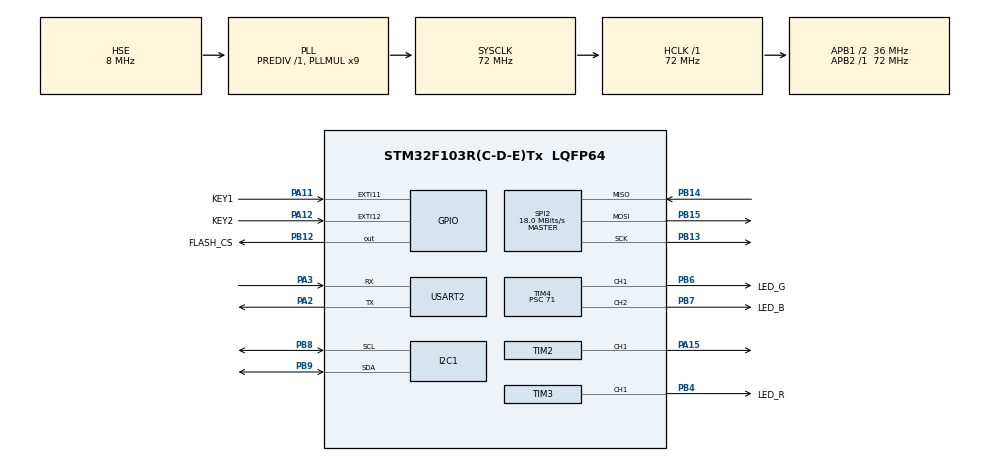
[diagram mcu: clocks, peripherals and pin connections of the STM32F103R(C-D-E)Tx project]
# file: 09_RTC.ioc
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Mcu.Family=STM32F1
Mcu.Name=STM32F103R(C-D-E)Tx
Mcu.Package=LQFP64
NVIC.PriorityGroup=NVIC_PRIORITYGROUP_4
NVIC.RTC_IRQn=true\:0\:0\:false\:false\:true\:true\:true\:true
NVIC.USART2_IRQn=true\:0\:0\:false\:false\:true\:true\:true\:true
PA11.GPIO_Label=KEY1
PA11.GPIO_ModeDefaultEXTI=GPIO_MODE_IT_RISING_FALLING
PA11.GPIO_PuPd=GPIO_PULLUP
PA11.Signal=GPXTI11
PA12.GPIO_Label=KEY2
PA12.GPIO_ModeDefaultEXTI=GPIO_MODE_IT_RISING_FALLING
PA12.GPIO_PuPd=GPIO_PULLUP
PA12.Signal=GPXTI12
PA13.Mode=Serial_Wire
PA13.Signal=SYS_JTMS-SWDIO
PA14.Mode=Serial_Wire
PA14.Signal=SYS_JTCK-SWCLK
PA15.GPIO_Speed=GPIO_SPEED_FREQ_HIGH
PA15.Signal=S_TIM2_CH1_ETR
PA2.Mode=Asynchronous
PA2.Signal=USART2_TX
PA3.Mode=Asynchronous
PA3.Signal=USART2_RX
PB12.GPIO_Label=FLASH_CS
PB12.GPIO_PuPd=GPIO_PULLUP
PB12.GPIO_Speed=GPIO_SPEED_FREQ_HIGH
PB12.PinState=GPIO_PIN_SET
PB12.Signal=GPIO_Output
PB13.Mode=Full_Duplex_Master
PB13.Signal=SPI2_SCK
PB14.Mode=Full_Duplex_Master
PB14.Signal=SPI2_MISO
PB15.Mode=Full_Duplex_Master
PB15.Signal=SPI2_MOSI
PB4.GPIO_Label=LED_R
PB4.GPIO_Speed=GPIO_SPEED_FREQ_HIGH
PB4.Signal=S_TIM3_CH1
PB6.GPIO_Label=LED_G
PB6.GPIO_Speed=GPIO_SPEED_FREQ_HIGH
PB6.Signal=S_TIM4_CH1
PB7.GPIO_Label=LED_B
PB7.GPIO_Speed=GPIO_SPEED_FREQ_HIGH
PB7.Signal=S_TIM4_CH2
PB8.Mode=I2C
PB8.Signal=I2C1_SCL
PB9.Mode=I2C
PB9.Signal=I2C1_SDA
PC14-OSC32_IN.Mode=LSE-External-Oscillator
PC14-OSC32_IN.Signal=RCC_OSC32_IN
PC15-OSC32_OUT.Mode=LSE-External-Oscillator
PC15-OSC32_OUT.Signal=RCC_OSC32_OUT
PD0-OSC_IN.Mode=HSE-External-Oscillator
PD0-OSC_IN.Signal=RCC_OSC_IN
PD1-OSC_OUT.Mode=HSE-External-Oscillator
PD1-OSC_OUT.Signal=RCC_OSC_OUT
ProjectManager.HeapSize=0x200
ProjectManager.StackSize=0x400
ProjectManager.TargetToolchain=MDK-ARM V5.32
RCC.AHBFreq_Value=72000000
RCC.APB1CLKDivider=RCC_HCLK_DIV2
RCC.APB1Freq_Value=36000000
RCC.APB1TimFreq_Value=72000000
RCC.APB2Freq_Value=72000000
RCC.APB2TimFreq_Value=72000000
RCC.HCLKFreq_Value=72000000
RCC.PLLMUL=RCC_PLL_MUL9
RCC.PLLSourceVirtual=RCC_PLLSOURCE_HSE
RCC.RTCClockSelection=RCC_RTCCLKSOURCE_LSE
RCC.SYSCLKFreq_VALUE=72000000
RCC.SYSCLKSource=RCC_SYSCLKSOURCE_PLLCLK
RCC.USBFreq_Value=72000000
RTC.AutoPrediv=RTC_AUTO_1_SECOND
RTC.Date=27
RTC.Format=RTC_FORMAT_BCD
RTC.Minutes=59
RTC.Month=RTC_MONTH_DECEMBER
RTC.OutPut=RTC_OUTPUTSOURCE_ALARM
RTC.Seconds=16
RTC.WeekDay=RTC_WEEKDAY_SATURDAY
RTC.Year=25
SH.S_TIM2_CH1_ETR.0=TIM2_CH1,PWM Generation1 CH1
SH.S_TIM3_CH1.0=TIM3_CH1,PWM Generation1 CH1
SH.S_TIM4_CH1.0=TIM4_CH1,PWM Generation1 CH1
SH.S_TIM4_CH2.0=TIM4_CH2,PWM Generation2 CH2
SPI2.CLKPhase=SPI_PHASE_2EDGE
SPI2.CLKPolarity=SPI_POLARITY_HIGH
SPI2.CalculateBaudRate=18.0 MBits/s
SPI2.Direction=SPI_DIRECTION_2LINES
SPI2.Mode=SPI_MODE_MASTER
SPI2.VirtualType=VM_MASTER
TIM1.AutoReloadPreload=TIM_AUTORELOAD_PRELOAD_ENABLE
TIM1.Period=9999
TIM1.Prescaler=71
TIM2.Channel-PWM\ Generation1\ CH1=TIM_CHANNEL_1
TIM2.OCPolarity_1=TIM_OCPOLARITY_LOW
TIM2.Period=99
TIM2.Prescaler=71
TIM3.AutoReloadPreload=TIM_AUTORELOAD_PRELOAD_ENABLE
TIM3.Channel-PWM\ Generation1\ CH1=TIM_CHANNEL_1
TIM3.OCPolarity_1=TIM_OCPOLARITY_LOW
TIM3.Period=4999
TIM3.Prescaler=71
TIM4.AutoReloadPreload=TIM_AUTORELOAD_PRELOAD_ENABLE
TIM4.Channel-PWM\ Generation1\ CH1=TIM_CHANNEL_1
TIM4.Channel-PWM\ Generation2\ CH2=TIM_CHANNEL_2
TIM4.OCPolarity_1=TIM_OCPOLARITY_LOW
TIM4.OCPolarity_2=TIM_OCPOLARITY_LOW
TIM4.Period=4999
TIM4.Prescaler=71
USART2.VirtualMode=VM_ASYNC
VP_RTC_VS_RTC_Activate.Mode=RTC_Enabled
VP_RTC_VS_RTC_Calendar.Mode=RTC_Calendar
VP_TIM1_VS_ClockSourceINT.Mode=Internal
VP_TIM2_VS_ClockSourceINT.Mode=Internal
VP_TIM3_VS_ClockSourceINT.Mode=Internal
VP_TIM4_VS_ClockSourceINT.Mode=Internal
board=custom

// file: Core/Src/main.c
/* USER CODE BEGIN Header */
/**
  ******************************************************************************
  * @file           : main.c
  * @brief          : Main program body
  ******************************************************************************
  * @attention
  *
  * Copyright (c) 2025 STMicroelectronics.
  * All rights reserved.
  *
  * This software is licensed under terms that can be found in the LICENSE file
  * in the root directory of this software component.
  * If no LICENSE file comes with this software, it is provided AS-IS.
  *
  ******************************************************************************
  */
/* USER CODE END Header */
#include "main.h"
#include "i2c.h"
#include "rtc.h"
#include "spi.h"
#include "tim.h"
#include "usart.h"
#include "gpio.h"

/* USER CODE BEGIN PV */
RTC_TimeTypeDef localTime = {0};
RTC_DateTypeDef localData = {0};
/* USER CODE END PV */

void SystemClock_Config(void);

int main(void)
{

  /* MCU Configuration--------------------------------------------------------*/

  /* Reset of all peripherals, Initializes the Flash interface and the Systick. */
  HAL_Init();

  /* Configure the system clock */
  SystemClock_Config();

  /* Initialize all configured peripherals */
  MX_GPIO_Init();
  MX_TIM1_Init();
  MX_TIM3_Init();
  MX_TIM4_Init();
  MX_TIM2_Init();
  MX_USART2_UART_Init();
  MX_SPI2_Init();
  MX_I2C1_Init();
  MX_RTC_Init();
  /* USER CODE BEGIN 2 */
  __HAL_RTC_SECOND_ENABLE_IT(&hrtc, RTC_IT_SEC);	//开启秒更新中断
  /* USER CODE END 2 */

  /* Infinite loop */
  /* USER CODE BEGIN WHILE */
  while (1)
  {

    HAL_Delay(800);
    /* USER CODE END WHILE */

  }
}

void SystemClock_Config(void)
{
  RCC_OscInitTypeDef RCC_OscInitStruct = {0};
  RCC_ClkInitTypeDef RCC_ClkInitStruct = {0};
  RCC_PeriphCLKInitTypeDef PeriphClkInit = {0};

  /** Initializes the RCC Oscillators according to the specified parameters
  * in the RCC_OscInitTypeDef structure.
  */
  RCC_OscInitStruct.OscillatorType = RCC_OSCILLATORTYPE_HSE|RCC_OSCILLATORTYPE_LSE;
  RCC_OscInitStruct.HSEState = RCC_HSE_ON;
  RCC_OscInitStruct.HSEPredivValue = RCC_HSE_PREDIV_DIV1;
  RCC_OscInitStruct.LSEState = RCC_LSE_ON;
  RCC_OscInitStruct.HSIState = RCC_HSI_ON;
  RCC_OscInitStruct.PLL.PLLState = RCC_PLL_ON;
  RCC_OscInitStruct.PLL.PLLSource = RCC_PLLSOURCE_HSE;
  RCC_OscInitStruct.PLL.PLLMUL = RCC_PLL_MUL9;
  if (HAL_RCC_OscConfig(&RCC_OscInitStruct) != HAL_OK)
  {
    Error_Handler();
  }

  /** Initializes the CPU, AHB and APB buses clocks
  */
  RCC_ClkInitStruct.ClockType = RCC_CLOCKTYPE_HCLK|RCC_CLOCKTYPE_SYSCLK
                              |RCC_CLOCKTYPE_PCLK1|RCC_CLOCKTYPE_PCLK2;
  RCC_ClkInitStruct.SYSCLKSource = RCC_SYSCLKSOURCE_PLLCLK;
  RCC_ClkInitStruct.AHBCLKDivider = RCC_SYSCLK_DIV1;
  RCC_ClkInitStruct.APB1CLKDivider = RCC_HCLK_DIV2;
  RCC_ClkInitStruct.APB2CLKDivider = RCC_HCLK_DIV1;

  if (HAL_RCC_ClockConfig(&RCC_ClkInitStruct, FLASH_LATENCY_2) != HAL_OK)
  {
    Error_Handler();
  }
  PeriphClkInit.PeriphClockSelection = RCC_PERIPHCLK_RTC;
  PeriphClkInit.RTCClockSelection = RCC_RTCCLKSOURCE_LSE;
  if (HAL_RCCEx_PeriphCLKConfig(&PeriphClkInit) != HAL_OK)
  {
    Error_Handler();
  }
}

/* USER CODE BEGIN 4 */
void HAL_RTCEx_RTCEventCallback(RTC_HandleTypeDef *hrtc)
{
  HAL_RTC_GetTime(hrtc,&localTime,RTC_FORMAT_BCD);
  HAL_RTC_GetDate(hrtc,&localData,RTC_FORMAT_BCD);
  MyPrintf("year: %x, month: %x, day: %x, hours: %x, minutes: %x, seconds: %x\r\n",localData.Date,localData.Month,localData.Date,localTime.Hours,localTime.Minutes,localTime.Seconds);
}
/* USER CODE END 4 */

void Error_Handler(void)
{
  __disable_irq();
  while (1)
  {
  }
}
